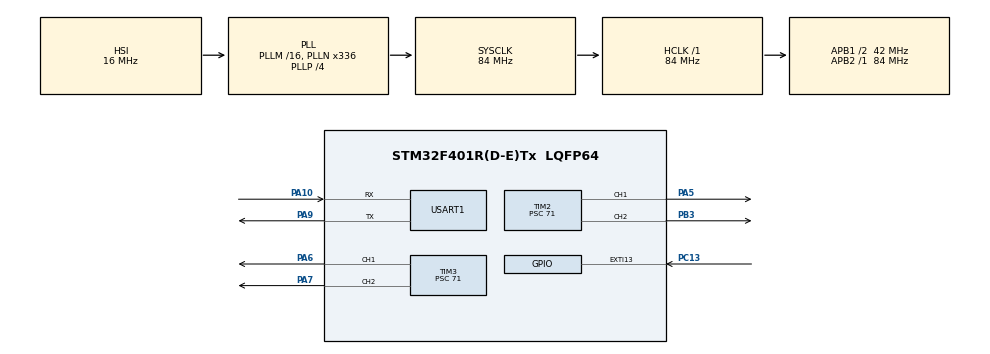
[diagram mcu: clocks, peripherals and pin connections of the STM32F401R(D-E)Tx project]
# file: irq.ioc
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Mcu.Family=STM32F4
Mcu.Name=STM32F401R(D-E)Tx
Mcu.Package=LQFP64
NVIC.PriorityGroup=NVIC_PRIORITYGROUP_4
NVIC.USART1_IRQn=true\:0\:0\:false\:false\:true\:true\:true\:true
PA10.Mode=Asynchronous
PA10.Signal=USART1_RX
PA5.Signal=S_TIM2_CH1_ETR
PA6.Signal=S_TIM3_CH1
PA7.Signal=S_TIM3_CH2
PA9.Mode=Asynchronous
PA9.Signal=USART1_TX
PB3.Signal=S_TIM2_CH2
PC13-ANTI_TAMP.Signal=GPXTI13
ProjectManager.HeapSize=0x200
ProjectManager.StackSize=0x400
ProjectManager.TargetToolchain=STM32CubeIDE
RCC.48MHZClocksFreq_Value=48000000
RCC.AHBFreq_Value=84000000
RCC.APB1CLKDivider=RCC_HCLK_DIV2
RCC.APB1Freq_Value=42000000
RCC.APB1TimFreq_Value=84000000
RCC.APB2Freq_Value=84000000
RCC.APB2TimFreq_Value=84000000
RCC.CortexFreq_Value=84000000
RCC.HCLKFreq_Value=84000000
RCC.HSE_VALUE=8000000
RCC.HSI_VALUE=16000000
RCC.LSE_VALUE=32768
RCC.PLLN=336
RCC.PLLP=RCC_PLLP_DIV4
RCC.PLLQ=7
RCC.SYSCLKFreq_VALUE=84000000
RCC.SYSCLKSource=RCC_SYSCLKSOURCE_PLLCLK
RCC.VCOOutputFreq_Value=336000000
SH.S_TIM2_CH1_ETR.0=TIM2_CH1,PWM Generation1 CH1
SH.S_TIM2_CH2.0=TIM2_CH2,PWM Generation2 CH2
SH.S_TIM3_CH1.0=TIM3_CH1,PWM Generation1 CH1
SH.S_TIM3_CH2.0=TIM3_CH2,PWM Generation2 CH2
TIM2.Channel-PWM\ Generation1\ CH1=TIM_CHANNEL_1
TIM2.Channel-PWM\ Generation2\ CH2=TIM_CHANNEL_2
TIM2.Period=999
TIM2.Prescaler=71
TIM3.Channel-PWM\ Generation1\ CH1=TIM_CHANNEL_1
TIM3.Channel-PWM\ Generation2\ CH2=TIM_CHANNEL_2
TIM3.Period=999
TIM3.Prescaler=71
USART1.VirtualMode=VM_ASYNC
board=NUCLEO-F401RE

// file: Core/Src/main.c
/* USER CODE BEGIN Header */
/**
  ******************************************************************************
  * @file           : main.c
  * @brief          : Main program body
  ******************************************************************************
  * @attention
  *
  * Copyright (c) 2025 STMicroelectronics.
  * All rights reserved.
  *
  * This software is licensed under terms that can be found in the LICENSE file
  * in the root directory of this software component.
  * If no LICENSE file comes with this software, it is provided AS-IS.
  *
  ******************************************************************************
  */
/* USER CODE END Header */
#include "main.h"

/* USER CODE BEGIN Includes */
#include "uart_handler.h"
#include "motor_control.h"
/* USER CODE END Includes */

TIM_HandleTypeDef htim2;
TIM_HandleTypeDef htim3;

UART_HandleTypeDef huart1;

/* USER CODE BEGIN PV */
uint8_t rx_byte = 0;
/* USER CODE END PV */

void SystemClock_Config(void);
static void MX_GPIO_Init(void);
static void MX_TIM2_Init(void);
static void MX_TIM3_Init(void);
static void MX_USART1_UART_Init(void);

/* USER CODE BEGIN 0 */
extern volatile uint8_t command_flag;
extern volatile uint8_t command_param;

int __io_putchar(int ch)
{
    HAL_UART_Transmit(&huart1, (uint8_t *)&ch, 1, HAL_MAX_DELAY);
    return ch;
}

/* USER CODE END 0 */

int main(void)
{

  /* MCU Configuration--------------------------------------------------------*/

  /* Reset of all peripherals, Initializes the Flash interface and the Systick. */
  HAL_Init();

  /* Configure the system clock */
  SystemClock_Config();

  /* Initialize all configured peripherals */
  MX_GPIO_Init();
  MX_TIM2_Init();
  MX_TIM3_Init();
  MX_USART1_UART_Init();
  /* USER CODE BEGIN 2 */
  // 시스템 시작 표시

  // L9110s 모터 드라이버 초기화 (motor_control.c의 함수 사용)
  L9110s_Init();

  // 시스템 상태 및 명령 도움말 표시

  /* USER CODE END 2 */

  /* Infinite loop */
  /* USER CODE BEGIN WHILE */
  HAL_UART_Receive_IT(&huart1, &rx_byte, 1);  // 1바이트 수신 인터럽트 활성화
  while (1) {
      if (command_flag) {
          UART_ProcessCommand(command_param);
          command_flag = 0;
      }
      HAL_Delay(1);
  }
  /* USER CODE END 3 */
}

void SystemClock_Config(void)
{
  RCC_OscInitTypeDef RCC_OscInitStruct = {0};
  RCC_ClkInitTypeDef RCC_ClkInitStruct = {0};

  /** Configure the main internal regulator output voltage
  */
  __HAL_RCC_PWR_CLK_ENABLE();
  __HAL_PWR_VOLTAGESCALING_CONFIG(PWR_REGULATOR_VOLTAGE_SCALE2);

  /** Initializes the RCC Oscillators according to the specified parameters
  * in the RCC_OscInitTypeDef structure.
  */
  RCC_OscInitStruct.OscillatorType = RCC_OSCILLATORTYPE_HSI;
  RCC_OscInitStruct.HSIState = RCC_HSI_ON;
  RCC_OscInitStruct.HSICalibrationValue = RCC_HSICALIBRATION_DEFAULT;
  RCC_OscInitStruct.PLL.PLLState = RCC_PLL_ON;
  RCC_OscInitStruct.PLL.PLLSource = RCC_PLLSOURCE_HSI;
  RCC_OscInitStruct.PLL.PLLM = 16;
  RCC_OscInitStruct.PLL.PLLN = 336;
  RCC_OscInitStruct.PLL.PLLP = RCC_PLLP_DIV4;
  RCC_OscInitStruct.PLL.PLLQ = 7;
  if (HAL_RCC_OscConfig(&RCC_OscInitStruct) != HAL_OK)
  {
    Error_Handler();
  }

  /** Initializes the CPU, AHB and APB buses clocks
  */
  RCC_ClkInitStruct.ClockType = RCC_CLOCKTYPE_HCLK|RCC_CLOCKTYPE_SYSCLK
                              |RCC_CLOCKTYPE_PCLK1|RCC_CLOCKTYPE_PCLK2;
  RCC_ClkInitStruct.SYSCLKSource = RCC_SYSCLKSOURCE_PLLCLK;
  RCC_ClkInitStruct.AHBCLKDivider = RCC_SYSCLK_DIV1;
  RCC_ClkInitStruct.APB1CLKDivider = RCC_HCLK_DIV2;
  RCC_ClkInitStruct.APB2CLKDivider = RCC_HCLK_DIV1;

  if (HAL_RCC_ClockConfig(&RCC_ClkInitStruct, FLASH_LATENCY_2) != HAL_OK)
  {
    Error_Handler();
  }
}

static void MX_TIM2_Init(void)
{

  TIM_MasterConfigTypeDef sMasterConfig = {0};
  TIM_OC_InitTypeDef sConfigOC = {0};

  htim2.Instance = TIM2;
  htim2.Init.Prescaler = 71;
  htim2.Init.CounterMode = TIM_COUNTERMODE_UP;
  htim2.Init.Period = 999;
  htim2.Init.ClockDivision = TIM_CLOCKDIVISION_DIV1;
  htim2.Init.AutoReloadPreload = TIM_AUTORELOAD_PRELOAD_DISABLE;
  if (HAL_TIM_PWM_Init(&htim2) != HAL_OK)
  {
    Error_Handler();
  }
  sMasterConfig.MasterOutputTrigger = TIM_TRGO_RESET;
  sMasterConfig.MasterSlaveMode = TIM_MASTERSLAVEMODE_DISABLE;
  if (HAL_TIMEx_MasterConfigSynchronization(&htim2, &sMasterConfig) != HAL_OK)
  {
    Error_Handler();
  }
  sConfigOC.OCMode = TIM_OCMODE_PWM1;
  sConfigOC.Pulse = 0;
  sConfigOC.OCPolarity = TIM_OCPOLARITY_HIGH;
  sConfigOC.OCFastMode = TIM_OCFAST_DISABLE;
  if (HAL_TIM_PWM_ConfigChannel(&htim2, &sConfigOC, TIM_CHANNEL_1) != HAL_OK)
  {
    Error_Handler();
  }
  if (HAL_TIM_PWM_ConfigChannel(&htim2, &sConfigOC, TIM_CHANNEL_2) != HAL_OK)
  {
    Error_Handler();
  }
  HAL_TIM_MspPostInit(&htim2);

}

static void MX_TIM3_Init(void)
{

  TIM_MasterConfigTypeDef sMasterConfig = {0};
  TIM_OC_InitTypeDef sConfigOC = {0};

  htim3.Instance = TIM3;
  htim3.Init.Prescaler = 71;
  htim3.Init.CounterMode = TIM_COUNTERMODE_UP;
  htim3.Init.Period = 999;
  htim3.Init.ClockDivision = TIM_CLOCKDIVISION_DIV1;
  htim3.Init.AutoReloadPreload = TIM_AUTORELOAD_PRELOAD_DISABLE;
  if (HAL_TIM_PWM_Init(&htim3) != HAL_OK)
  {
    Error_Handler();
  }
  sMasterConfig.MasterOutputTrigger = TIM_TRGO_RESET;
  sMasterConfig.MasterSlaveMode = TIM_MASTERSLAVEMODE_DISABLE;
  if (HAL_TIMEx_MasterConfigSynchronization(&htim3, &sMasterConfig) != HAL_OK)
  {
    Error_Handler();
  }
  sConfigOC.OCMode = TIM_OCMODE_PWM1;
  sConfigOC.Pulse = 0;
  sConfigOC.OCPolarity = TIM_OCPOLARITY_HIGH;
  sConfigOC.OCFastMode = TIM_OCFAST_DISABLE;
  if (HAL_TIM_PWM_ConfigChannel(&htim3, &sConfigOC, TIM_CHANNEL_1) != HAL_OK)
  {
    Error_Handler();
  }
  if (HAL_TIM_PWM_ConfigChannel(&htim3, &sConfigOC, TIM_CHANNEL_2) != HAL_OK)
  {
    Error_Handler();
  }
  HAL_TIM_MspPostInit(&htim3);

}

static void MX_USART1_UART_Init(void)
{

  huart1.Instance = USART1;
  huart1.Init.BaudRate = 115200;
  huart1.Init.WordLength = UART_WORDLENGTH_8B;
  huart1.Init.StopBits = UART_STOPBITS_1;
  huart1.Init.Parity = UART_PARITY_NONE;
  huart1.Init.Mode = UART_MODE_TX_RX;
  huart1.Init.HwFlowCtl = UART_HWCONTROL_NONE;
  huart1.Init.OverSampling = UART_OVERSAMPLING_16;
  if (HAL_UART_Init(&huart1) != HAL_OK)
  {
    Error_Handler();
  }

}

static void MX_GPIO_Init(void)
{
  GPIO_InitTypeDef GPIO_InitStruct = {0};

  /* GPIO Ports Clock Enable */
  __HAL_RCC_GPIOC_CLK_ENABLE();
  __HAL_RCC_GPIOA_CLK_ENABLE();
  __HAL_RCC_GPIOB_CLK_ENABLE();

  /*Configure GPIO pin : PC13 */
  GPIO_InitStruct.Pin = GPIO_PIN_13;
  GPIO_InitStruct.Mode = GPIO_MODE_IT_RISING;
  GPIO_InitStruct.Pull = GPIO_NOPULL;
  HAL_GPIO_Init(GPIOC, &GPIO_InitStruct);

}

void Error_Handler(void)
{
  __disable_irq();
  while (1)
  {
  }
}
